# Test register map
Vendor: zermio; File version: 0.1
CPU: reis-riscv r0p1, little endian, no MPU, no FPU, VTOR, 2 interrupt priority bits, 1 interrupts
Registers are 32-bit, read-write, reset 0x0 unless marked. A register's access mark holds for its fields unless they carry their own. Offsets are from the block's base; [hi:lo] are bit positions.

## I2C0 — I2C interface for host and device mode, supporting up to 1 Mbaud data rates
Base 0x80200000
Same registers: I2C1 0x80200100
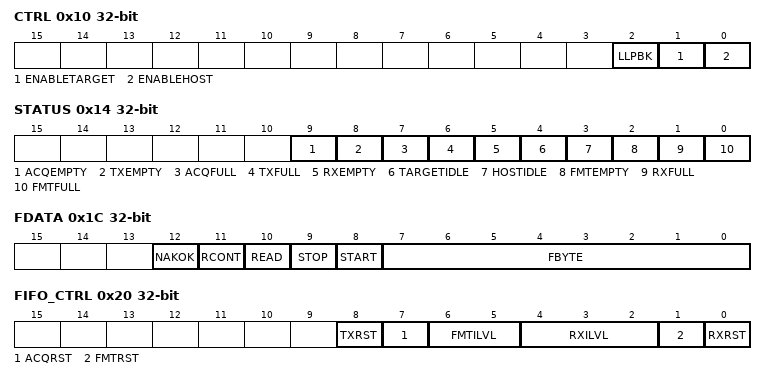
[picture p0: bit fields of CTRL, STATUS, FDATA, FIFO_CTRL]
0x10 CTRL reset not defined — I2C Control Register
  [2] LLPBK — Enable I2C line loopback testIf line loopback is enabled, the internal design sees ACQ and RX data as "1"
  [1] ENABLETARGET — Enable Target I2C functionality
  [0] ENABLEHOST — Enable Host I2C functionality
0x14 STATUS ro reset not defined — I2C Live Status Register
  [9] ACQEMPTY — ACQ FIFO is empty
  [8] TXEMPTY — TX FIFO is empty
  [7] ACQFULL — ACQ FIFO is full
  [6] TXFULL — TX FIFO is full
  [5] RXEMPTY — RX FIFO is empty
  [4] TARGETIDLE — Target functionality is idle. No Target transaction is in progress
  [3] HOSTIDLE — Host functionality is idle. No Host transaction is in progress
  [2] FMTEMPTY — FMT FIFO is empty
  [1] RXFULL — RX FIFO is full
  [0] FMTFULL — FMT FIFO is full
0x18 RDATA ro reset not defined — I2C Read Data
  [7:0] Value
0x1C FDATA wo reset not defined — I2C Format Data
  [12] NAKOK — Do not signal an exception if the current byte is not ACK'd
  [11] RCONT — Do not NACK the last byte read, let the read operation continue
  [10] READ — Read BYTE bytes from I2C. (256 if BYTE==0)
  [9] STOP — Issue a STOP condition after this operation
  [8] START — Issue a START condition before transmitting BYTE.
  [7:0] FBYTE — Format Byte. Directly transmitted if no flags are set.
0x20 FIFO_CTRL reset not defined — I2C FIFO control register
  [8] TXRST — TX FIFO reset. Write 1 to the register resets it. Read returns 0
  [7] ACQRST — ACQ FIFO reset. Write 1 to the register resets it. Read returns 0
  [6:5] FMTILVL — Trigger level for FMT interrupts. If the FIFO depth falls belowthis setting, it raises fmt_threshold interrupt.
  [4:2] RXILVL — Trigger level for RX interrupts. If the FIFO depth exceedsthis setting, it raises rx_threshold interrupt.
  [1] FMTRST — FMT fifo reset. Write 1 to the register resets FMT_FIFO. Read returns 0
  [0] RXRST — RX fifo reset. Write 1 to the register resets RX_FIFO. Read returns 0
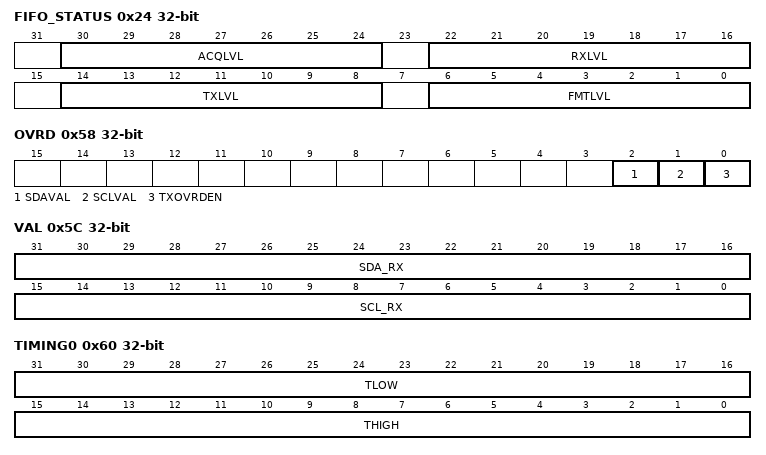
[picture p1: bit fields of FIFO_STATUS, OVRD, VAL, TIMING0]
0x24 FIFO_STATUS ro reset not defined — I2C FIFO status register
  [30:24] ACQLVL — Current fill level of ACQ fifo
  [22:16] RXLVL — Current fill level of RX fifo
  [14:8] TXLVL — Current fill level of TX fifo
  [6:0] FMTLVL — Current fill level of FMT fifo
0x58 OVRD reset not defined — I2C Override Control Register
  [2] SDAVAL — Value for SDA Override. Set to 0 to drive TX Low, and set to 1 for high-Z
  [1] SCLVAL — Value for SCL Override. Set to 0 to drive TX Low, and set to 1 for high-Z
  [0] TXOVRDEN — Override the SDA and SCL TX signals.
0x5C VAL ro reset not defined — Oversampled RX values
  [31:16] SDA_RX — Last 16 oversampled values of SDA. Most recent bit is bit 16, oldest 31.
  [15:0] SCL_RX — Last 16 oversampled values of SCL. Most recent bit is bit 0, oldest 15.
0x60 TIMING0 reset not defined — Detailed I2C Timings (directly corresponding to table 10 in the I2C Specification).All values are expressed in units of the input clock period.These must be greater than 2 in order for the change in SCL to propagate to the input of the FSM so that acknowledgements are detected correctly.
  [31:16] TLOW — The actual time to hold SCL low between any two SCL pulses
  [15:0] THIGH — The actual time to hold SCL high in a given pulse: in host mode, when there is no stretching this value is 3 cycles longer as tracked in issue #18962
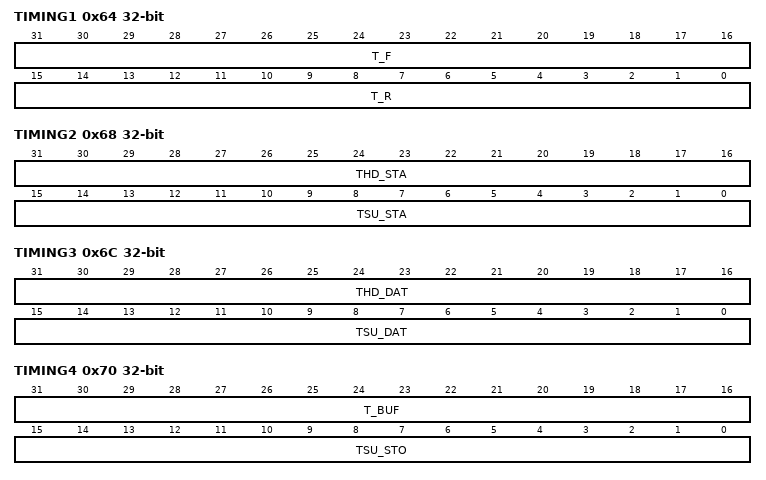
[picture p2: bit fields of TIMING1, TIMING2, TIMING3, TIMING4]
0x64 TIMING1 reset not defined — Detailed I2C Timings (directly corresponding to table 10 in the I2C Specification).All values are expressed in units of the input clock period.
  [31:16] T_F — The nominal fall time to anticipate for the bus (influences SDA hold times): this is currently counted twice in host mode as tracked in issue #18958
  [15:0] T_R — The nominal rise time to anticipate for the bus (depends on capacitance)
0x68 TIMING2 reset not defined — Detailed I2C Timings (directly corresponding to table 10 in the I2C Specification).All values are expressed in units of the input clock period.
  [31:16] THD_STA — Actual hold time for start signals
  [15:0] TSU_STA — Actual setup time for repeated start signals
0x6C TIMING3 reset not defined — Detailed I2C Timings (directly corresponding to table 10, in the I2C Specification).All values are expressed in units of the input clock period.
  [31:16] THD_DAT — Actual hold time for data (or ack) bits(Note, where required, the parameters TVD_DAT is taken to be THD_DAT+T_F)
  [15:0] TSU_DAT — Actual setup time for data (or ack) bits
0x70 TIMING4 reset not defined — Detailed I2C Timings (directly corresponding to table 10, in the I2C Specification).All values are expressed in units of the input clock period.
  [31:16] T_BUF — Actual time between each STOP signal and the following START signal
  [15:0] TSU_STO — Actual setup time for stop signals
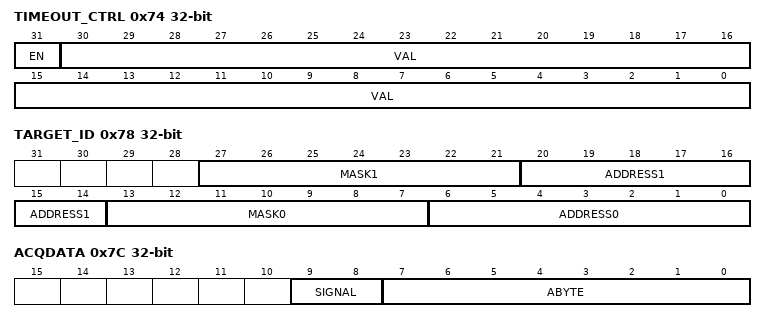
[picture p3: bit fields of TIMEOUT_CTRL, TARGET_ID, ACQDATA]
0x74 TIMEOUT_CTRL reset not defined — I2C clock stretching timeout control
  [31] EN — Enable timeout feature
  [30:0] VAL — Clock stretching timeout value (in units of input clock frequency)
0x78 TARGET_ID reset not defined — I2C target address and mask pairs
  [27:21] MASK1 — I2C target mask number 1
  [20:14] ADDRESS1 — I2C target address number 1
  [13:7] MASK0 — I2C target mask number 0
  [6:0] ADDRESS0 — I2C target address number 0
0x7C ACQDATA ro reset not defined — I2C target acquired data
  [9:8] SIGNAL — Host issued a START before transmitting ABYTE, a STOP or a RESTART after the preceeding ABYTE
  [7:0] ABYTE — Address for accepted transaction or acquired byte
0x80 TXDATA wo reset not defined — I2C target transmit data
  [7:0] Value
0x84 HOST_TIMEOUT_CTRL reset not defined — I2C host clock generation timeout value (in units of input clock frequency)
  [31:0] Value
